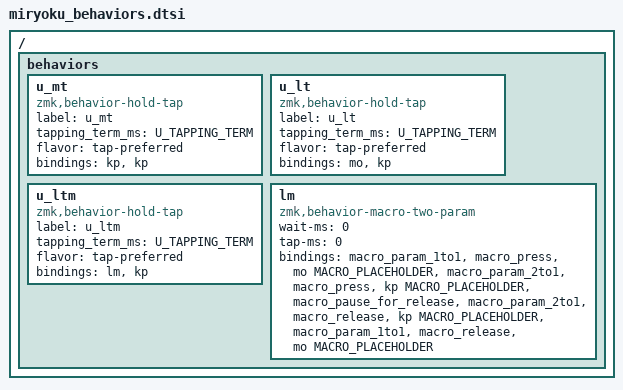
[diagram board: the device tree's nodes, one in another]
// Copyright 2022 Manna Harbour
// https://github.com/manna-harbour/miryoku

/ {
  behaviors {
    u_mt: u_mt {
      compatible = "zmk,behavior-hold-tap";
      label = "u_mt";
      #binding-cells = <2>;
      tapping_term_ms = <U_TAPPING_TERM>;
      flavor = "tap-preferred";
      bindings = <&kp>, <&kp>;
    };
    u_lt: u_lt {
      compatible = "zmk,behavior-hold-tap";
      label = "u_lt";
      #binding-cells = <2>;
      tapping_term_ms = <U_TAPPING_TERM>;
      flavor = "tap-preferred";
      bindings = <&mo>, <&kp>;
    };
    u_ltm: u_ltm {
      compatible = "zmk,behavior-hold-tap";
      label = "u_ltm";
      #binding-cells = <2>;
      tapping_term_ms = <U_TAPPING_TERM>;
      flavor = "tap-preferred";
      bindings = <&lm>, <&kp>;
    };
    lm: lm {
      compatible = "zmk,behavior-macro-two-param";
      wait-ms = <0>;
      tap-ms = <0>;
      #binding-cells = <2>;
      bindings
          = <&macro_param_1to1>
          , <&macro_press &mo MACRO_PLACEHOLDER>
          , <&macro_param_2to1>
          , <&macro_press &kp MACRO_PLACEHOLDER>
          , <&macro_pause_for_release>
          , <&macro_param_2to1>
          , <&macro_release &kp MACRO_PLACEHOLDER>
          , <&macro_param_1to1>
          , <&macro_release &mo MACRO_PLACEHOLDER>
          ;
    };
  };
};
